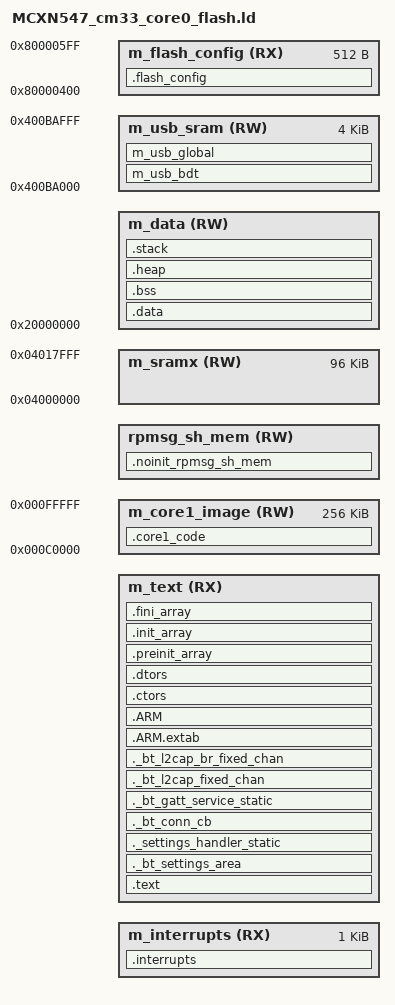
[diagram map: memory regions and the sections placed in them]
/*
** ###################################################################
**     Processors:          MCXN547VDF_cm33_core0
**                          MCXN547VNL_cm33_core0
**
**     Compiler:            GNU C Compiler
**     Reference manual:    MCXNx4x Reference Manual
**     Version:             rev. 1.0, 2021-08-03
**     Build:               b230607
**
**     Abstract:
**         Linker file for the GNU C Compiler
**
**     Copyright 2016 Freescale Semiconductor, Inc.
**     Copyright 2016-2023 NXP
**     SPDX-License-Identifier: BSD-3-Clause
**
**     http:                 www.nxp.com
**     mail:                 support@nxp.com
**
** ###################################################################
*/



/* Entry Point */
ENTRY(Reset_Handler)

HEAP_SIZE  = DEFINED(__heap_size__)  ? __heap_size__  : 0x1000;
STACK_SIZE = DEFINED(__stack_size__) ? __stack_size__ : 0x0800;
RPMSG_SHMEM_SIZE = DEFINED(__use_shmem__) ? 0x2000 : 0;

TEXT_START = DEFINED(__qspi_xip__)  ? 0x80001000 : 0x00000000; /* flexspi boot image start with 0x80000000 */
TEXT_SIZE = DEFINED(__qspi_xip__)  ? 0x0FFFF000 : 0x00200000; /* flexspi boot image offset at 0x80001000 */

LITTLEFS_REGION_SIZE = 0x00080000;

m_text_start         = TEXT_START;
m_text_size          = TEXT_SIZE - LITTLEFS_REGION_SIZE;

/* Specify the memory areas */
MEMORY
{
  m_interrupts          (RX)  : ORIGIN = m_text_start, LENGTH = 0x00000400
  m_text                (RX)  : ORIGIN = m_text_start + 0x00000400, LENGTH = m_text_size - 0x00000400
  m_data                (RW)  : ORIGIN = 0x20000000, LENGTH = 0x00060000 - RPMSG_SHMEM_SIZE
  m_core1_image         (RW)  : ORIGIN = 0x000C0000, LENGTH = 0x00040000
  rpmsg_sh_mem          (RW)  : ORIGIN = 0x2004E000 - RPMSG_SHMEM_SIZE, LENGTH = RPMSG_SHMEM_SIZE
  m_sramx               (RW)  : ORIGIN = 0x04000000, LENGTH = 0x00018000
  m_flash_config        (RX)  : ORIGIN = 0x80000400, LENGTH = 0x00000200
  m_usb_sram            (RW)  : ORIGIN = 0x400BA000, LENGTH = 0x00001000
}

/* NOTE: The last LITTLEFS_REGION_SIZE Flash( in range (m_text_start + m_text_size) ~ (m_text_start + m_text_size + LITTLEFS_REGION_SIZE -1)) is reserved for litteFS data */

/*** littleFS configuration Start ***/
EDGEFAST_BT_LITTLEFS_STORAGE_START_ADDRESS = m_text_start + m_text_size;
EDGEFAST_BT_LITTLEFS_STORAGE_SECTOR_SIZE   = 0x2000; /* 8k flash sector size */
EDGEFAST_BT_LITTLEFS_STORAGE_MAX_SECTORS   = LITTLEFS_REGION_SIZE / EDGEFAST_BT_LITTLEFS_STORAGE_SECTOR_SIZE;
/*** littleFS configuration End ***/

/* Define output sections */
SECTIONS
{
  /* section for storing the secondary core image */
  .core1_code :
  {
     . = ALIGN(4) ;
    KEEP (*(.core1_code))
     *(.core1_code*)
     . = ALIGN(4) ;
  } > m_core1_image

  /* NOINIT section for rpmsg_sh_mem */
  .noinit_rpmsg_sh_mem (NOLOAD) : ALIGN(4)
  {
     __RPMSG_SH_MEM_START__ = .;
     *(.noinit.$rpmsg_sh_mem*)
     . = ALIGN(4) ;
     __RPMSG_SH_MEM_END__ = .;
  } > rpmsg_sh_mem

  .flash_config :
  {
    . = ALIGN(4);
    __FLASH_BASE = .;
    KEEP(* (.flexspi_fcb))     /* FCB section */
    . = ALIGN(4);
  } > m_flash_config

  /* The startup code goes first into internal flash */
  .interrupts :
  {
    . = ALIGN(4);
    KEEP(*(.isr_vector))     /* Startup code */
    . = ALIGN(4);
  } > m_interrupts

  /* The program code and other data goes into internal flash */
  .text :
  {
    . = ALIGN(4);
    *(EXCLUDE_FILE(
        /* Exclude flash and frequently executed functions from XIP */
        */mflash_drv.c.obj
        */fsl_flexspi.c.obj
    ) .text)                 /* .text sections (code) */
    *(EXCLUDE_FILE(
        /* Exclude flash and frequently executed functions from XIP */
        */mflash_drv.c.obj
        */fsl_flexspi.c.obj
    ) .text*)                /* .text* sections (code) */
    *(.rodata)               /* .rodata sections (constants, strings, etc.) */
    *(.rodata*)              /* .rodata* sections (constants, strings, etc.) */
    *(.glue_7)               /* glue arm to thumb code */
    *(.glue_7t)              /* glue thumb to arm code */
    *(.eh_frame)
    KEEP (*(.init))
    KEEP (*(.fini))
    . = ALIGN(4);
  } > m_text
  ._bt_settings_area :
  {
    . = ALIGN(4);
    _bt_settings_start = .;
    KEEP(*(SORT(._bt_settings.static.*)))
    _bt_settings_end = .;
    . = ALIGN(4);
  } > m_text

  ._settings_handler_static :
  {
    . = ALIGN(4);
    _settings_handler_static_list_start = .;
    KEEP(*(SORT(._settings_handler_static.static.*)))
    _settings_handler_static_list_end = .;
    . = ALIGN(4);
  } > m_text

  ._bt_conn_cb :
  {
    . = ALIGN(4);
    _bt_conn_cb_list_start = .;
    KEEP(*(SORT(._bt_conn_cb.static.*)))
    _bt_conn_cb_list_end = .;
    . = ALIGN(4);
  } > m_text

  ._bt_gatt_service_static :
  {
    . = ALIGN(4);
    _bt_gatt_service_static_list_start = .;
    KEEP(*(SORT(._bt_gatt_service_static.static.*)))
    _bt_gatt_service_static_list_end = .;
    . = ALIGN(4);
  } > m_text

  ._bt_l2cap_fixed_chan :
  {
    . = ALIGN(4);
    _bt_l2cap_fixed_chan_list_start = .;
    KEEP(*(SORT(._bt_l2cap_fixed_chan.static.*)))
    _bt_l2cap_fixed_chan_list_end = .;
    . = ALIGN(4);
  } > m_text

  ._bt_l2cap_br_fixed_chan :
  {
    . = ALIGN(4);
    _bt_l2cap_br_fixed_chan_list_start = .;
    KEEP(*(SORT(._bt_l2cap_br_fixed_chan.static.*)))
    _bt_l2cap_br_fixed_chan_list_end = .;
    . = ALIGN(4);
  } > m_text

  .ARM.extab :
  {
    *(.ARM.extab* .gnu.linkonce.armextab.*)
  } > m_text

  .ARM :
  {
    __exidx_start = .;
    *(.ARM.exidx*)
    __exidx_end = .;
  } > m_text

 .ctors :
  {
    __CTOR_LIST__ = .;
    /* gcc uses crtbegin.o to find the start of
       the constructors, so we make sure it is
       first.  Because this is a wildcard, it
       doesn't matter if the user does not
       actually link against crtbegin.o; the
       linker won't look for a file to match a
       wildcard.  The wildcard also means that it
       doesn't matter which directory crtbegin.o
       is in.  */
    KEEP (*crtbegin.o(.ctors))
    KEEP (*crtbegin?.o(.ctors))
    /* We don't want to include the .ctor section from
       from the crtend.o file until after the sorted ctors.
       The .ctor section from the crtend file contains the
       end of ctors marker and it must be last */
    KEEP (*(EXCLUDE_FILE(*crtend?.o *crtend.o) .ctors))
    KEEP (*(SORT(.ctors.*)))
    KEEP (*(.ctors))
    __CTOR_END__ = .;
  } > m_text

  .dtors :
  {
    __DTOR_LIST__ = .;
    KEEP (*crtbegin.o(.dtors))
    KEEP (*crtbegin?.o(.dtors))
    KEEP (*(EXCLUDE_FILE(*crtend?.o *crtend.o) .dtors))
    KEEP (*(SORT(.dtors.*)))
    KEEP (*(.dtors))
    __DTOR_END__ = .;
  } > m_text

  .preinit_array :
  {
    PROVIDE_HIDDEN (__preinit_array_start = .);
    KEEP (*(.preinit_array*))
    PROVIDE_HIDDEN (__preinit_array_end = .);
  } > m_text

  .init_array :
  {
    PROVIDE_HIDDEN (__init_array_start = .);
    KEEP (*(SORT(.init_array.*)))
    KEEP (*(.init_array*))
    PROVIDE_HIDDEN (__init_array_end = .);
  } > m_text

  .fini_array :
  {
    PROVIDE_HIDDEN (__fini_array_start = .);
    KEEP (*(SORT(.fini_array.*)))
    KEEP (*(.fini_array*))
    PROVIDE_HIDDEN (__fini_array_end = .);
  } > m_text

  __etext = .;    /* define a global symbol at end of code */
  __DATA_ROM = .; /* Symbol is used by startup for data initialization */

  .data : AT(__DATA_ROM)
  {
    . = ALIGN(4);
    __DATA_RAM = .;
    __data_start__ = .;      /* create a global symbol at data start */
    *(.ramfunc*)             /* for functions in ram */
    /* Explicit placement of flash and frequently executed functions in RAM */
    */mflash_drv.c.obj
    */fsl_flexspi.c.obj
    *(.data)                 /* .data sections */
    *(.data*)                /* .data* sections */
    *(NonCacheable.init)     /* NonCacheable init section */
    *(NonCacheable)          /* NonCacheable section */
    *(CodeQuickAccess)       /* quick access code section */
    *(DataQuickAccess)       /* quick access data section */
    KEEP(*(.jcr*))
    . = ALIGN(4);
    _k_mem_slab_list_start = .;
    KEEP(*(SORT(._k_mem_slab*)))
    _k_mem_slab_list_end = .;
    . = ALIGN(4);
    _net_buf_pool_list = .;
    KEEP(*(SORT(._net_buf_pool*)))
    . = ALIGN(4);
    __data_end__ = .;        /* define a global symbol at data end */
  } > m_data

  __DATA_END = __DATA_ROM + (__data_end__ - __data_start__);
  text_end = ORIGIN(m_text) + LENGTH(m_text);
  ASSERT(__DATA_END <= text_end, "region m_text overflowed with text and data")

  /* Uninitialized data section */
  .bss :
  {
    /* This is used by the startup in order to initialize the .bss section */
    . = ALIGN(4);
    __START_BSS = .;
    __bss_start__ = .;
    *(.bss)
    *(.bss*)
    *(COMMON)
    . = ALIGN(4);
    __bss_end__ = .;
    __END_BSS = .;
  } > m_data

  .heap :
  {
    . = ALIGN(8);
    __end__ = .;
    PROVIDE(end = .);
    __HeapBase = .;
    . += HEAP_SIZE;
    __HeapLimit = .;
    __heap_limit = .; /* Add for _sbrk */
  } > m_data

  .stack :
  {
    . = ALIGN(8);
    . += STACK_SIZE;
  } > m_data

  m_usb_bdt (NOLOAD) :
  {
    . = ALIGN(512);
    *(m_usb_bdt)
  } > m_usb_sram

  m_usb_global (NOLOAD) :
  {
    *(m_usb_global)
  } > m_usb_sram

  /* Initializes stack on the end of block */
  __StackTop   = ORIGIN(m_data) + LENGTH(m_data);
  __StackLimit = __StackTop - STACK_SIZE;
  PROVIDE(__stack = __StackTop);

  .ARM.attributes 0 : { *(.ARM.attributes) }

  ASSERT(__StackLimit >= __HeapLimit, "region m_data overflowed with stack and heap")
}

